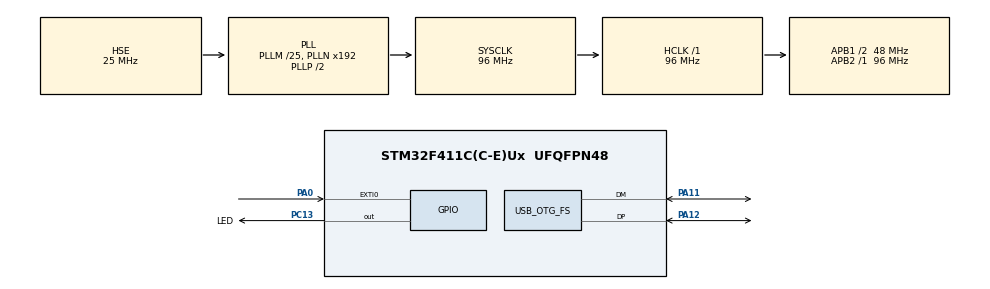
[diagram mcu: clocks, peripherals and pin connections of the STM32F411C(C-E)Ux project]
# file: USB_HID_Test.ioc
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FREERTOS.INCLUDE_pcTaskGetTaskName=1
FREERTOS.Tasks01=ledTask,24,2000,StartDefaultTask,Default,NULL,Static,ledTaskBuffer,ledTaskControlBlock
FREERTOS.configCHECK_FOR_STACK_OVERFLOW=1
FREERTOS.configMINIMAL_STACK_SIZE=1000
FREERTOS.configRECORD_STACK_HIGH_ADDRESS=1
FREERTOS.configUSE_APPLICATION_TASK_TAG=1
FREERTOS.configUSE_NEWLIB_REENTRANT=1
Mcu.Family=STM32F4
Mcu.Name=STM32F411C(C-E)Ux
Mcu.Package=UFQFPN48
NVIC.EXTI0_IRQn=true\:5\:0\:false\:false\:true\:true\:true\:true\:true
NVIC.OTG_FS_IRQn=true\:5\:0\:false\:false\:true\:true\:true\:true\:true
NVIC.PriorityGroup=NVIC_PRIORITYGROUP_4
NVIC.TIM1_UP_TIM10_IRQn=true\:15\:0\:false\:false\:true\:false\:false\:true\:true
NVIC.TimeBase=TIM1_UP_TIM10_IRQn
NVIC.TimeBaseIP=TIM10
PA0-WKUP.Signal=GPXTI0
PA11.Mode=Device_Only
PA11.Signal=USB_OTG_FS_DM
PA12.Mode=Device_Only
PA12.Signal=USB_OTG_FS_DP
PC13-ANTI_TAMP.GPIO_Label=LED
PC13-ANTI_TAMP.PinState=GPIO_PIN_SET
PC13-ANTI_TAMP.Signal=GPIO_Output
PC14-OSC32_IN.Mode=LSE-External-Oscillator
PC14-OSC32_IN.Signal=RCC_OSC32_IN
PC15-OSC32_OUT.Mode=LSE-External-Oscillator
PC15-OSC32_OUT.Signal=RCC_OSC32_OUT
PH0\ -\ OSC_IN.Mode=HSE-External-Oscillator
PH0\ -\ OSC_IN.Signal=RCC_OSC_IN
PH1\ -\ OSC_OUT.Mode=HSE-External-Oscillator
PH1\ -\ OSC_OUT.Signal=RCC_OSC_OUT
ProjectManager.HeapSize=0x1000
ProjectManager.StackSize=0x800
ProjectManager.TargetToolchain=STM32CubeIDE
RCC.48MHZClocksFreq_Value=48000000
RCC.AHBFreq_Value=96000000
RCC.APB1CLKDivider=RCC_HCLK_DIV2
RCC.APB1Freq_Value=48000000
RCC.APB1TimFreq_Value=96000000
RCC.APB2Freq_Value=96000000
RCC.APB2TimFreq_Value=96000000
RCC.CortexFreq_Value=96000000
RCC.HCLKFreq_Value=96000000
RCC.HSE_VALUE=25000000
RCC.HSI_VALUE=16000000
RCC.PLLM=25
RCC.SYSCLKFreq_VALUE=96000000
RCC.SYSCLKSource=RCC_SYSCLKSOURCE_PLLCLK
RCC.VCOOutputFreq_Value=192000000
USB_OTG_FS.VirtualMode=Device_Only
USB_OTG_FS.low_power_enable=DISABLE
USB_OTG_FS.lpm_enable=DISABLE
VP_FREERTOS_VS_CMSIS_V2.Mode=CMSIS_V2
VP_SYS_VS_tim10.Mode=TIM10
board=custom

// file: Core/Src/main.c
/* USER CODE BEGIN Header */
/**
  ******************************************************************************
  * @file           : main.c
  * @brief          : Main program body
  ******************************************************************************
  * @attention
  *
  * Copyright (c) 2025 STMicroelectronics.
  * All rights reserved.
  *
  * This software is licensed under terms that can be found in the LICENSE file
  * in the root directory of this software component.
  * If no LICENSE file comes with this software, it is provided AS-IS.
  *
  ******************************************************************************
  */
/* USER CODE END Header */
#include "main.h"
#include "cmsis_os.h"
#include "gpio.h"

/* USER CODE BEGIN Includes */
#include "usb_device.h"
/* USER CODE END Includes */

void SystemClock_Config(void);
void MX_FREERTOS_Init(void);

int main(void)
{

  /* MCU Configuration--------------------------------------------------------*/

  /* Reset of all peripherals, Initializes the Flash interface and the Systick. */
  HAL_Init();

  /* Configure the system clock */
  SystemClock_Config();

  /* Initialize all configured peripherals */
  MX_GPIO_Init();
  /* USER CODE BEGIN 2 */

  MX_USB_DEVICE_Init();

  /* USER CODE END 2 */

  /* Init scheduler */
  osKernelInitialize();  /* Call init function for freertos objects (in cmsis_os2.c) */
  MX_FREERTOS_Init();

  /* Start scheduler */
  osKernelStart();

  /* We should never get here as control is now taken by the scheduler */

  /* Infinite loop */
  while (1)
  {

    /* USER CODE BEGIN 3 */
	// We should never get here
  }
  /* USER CODE END 3 */
}

void SystemClock_Config(void)
{
  RCC_OscInitTypeDef RCC_OscInitStruct = {0};
  RCC_ClkInitTypeDef RCC_ClkInitStruct = {0};

  /** Configure the main internal regulator output voltage
  */
  __HAL_RCC_PWR_CLK_ENABLE();
  __HAL_PWR_VOLTAGESCALING_CONFIG(PWR_REGULATOR_VOLTAGE_SCALE1);

  /** Initializes the RCC Oscillators according to the specified parameters
  * in the RCC_OscInitTypeDef structure.
  */
  RCC_OscInitStruct.OscillatorType = RCC_OSCILLATORTYPE_HSE;
  RCC_OscInitStruct.HSEState = RCC_HSE_ON;
  RCC_OscInitStruct.PLL.PLLState = RCC_PLL_ON;
  RCC_OscInitStruct.PLL.PLLSource = RCC_PLLSOURCE_HSE;
  RCC_OscInitStruct.PLL.PLLM = 25;
  RCC_OscInitStruct.PLL.PLLN = 192;
  RCC_OscInitStruct.PLL.PLLP = RCC_PLLP_DIV2;
  RCC_OscInitStruct.PLL.PLLQ = 4;
  if (HAL_RCC_OscConfig(&RCC_OscInitStruct) != HAL_OK)
  {
    Error_Handler();
  }

  /** Initializes the CPU, AHB and APB buses clocks
  */
  RCC_ClkInitStruct.ClockType = RCC_CLOCKTYPE_HCLK|RCC_CLOCKTYPE_SYSCLK
                              |RCC_CLOCKTYPE_PCLK1|RCC_CLOCKTYPE_PCLK2;
  RCC_ClkInitStruct.SYSCLKSource = RCC_SYSCLKSOURCE_PLLCLK;
  RCC_ClkInitStruct.AHBCLKDivider = RCC_SYSCLK_DIV1;
  RCC_ClkInitStruct.APB1CLKDivider = RCC_HCLK_DIV2;
  RCC_ClkInitStruct.APB2CLKDivider = RCC_HCLK_DIV1;

  if (HAL_RCC_ClockConfig(&RCC_ClkInitStruct, FLASH_LATENCY_3) != HAL_OK)
  {
    Error_Handler();
  }
}

void HAL_TIM_PeriodElapsedCallback(TIM_HandleTypeDef *htim)
{
  if (htim->Instance == TIM10)
  {
    HAL_IncTick();
  }
}

void Error_Handler(void)
{
  __disable_irq();
  while (1)
  {
  }
}

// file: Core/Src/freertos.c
/* USER CODE BEGIN Header */
/**
  ******************************************************************************
  * File Name          : freertos.c
  * Description        : Code for freertos applications
  ******************************************************************************
  * @attention
  *
  * Copyright (c) 2025 STMicroelectronics.
  * All rights reserved.
  *
  * This software is licensed under terms that can be found in the LICENSE file
  * in the root directory of this software component.
  * If no LICENSE file comes with this software, it is provided AS-IS.
  *
  ******************************************************************************
  */
/* USER CODE END Header */

#include "FreeRTOS.h"
#include "task.h"
#include "main.h"
#include "cmsis_os.h"

/* USER CODE BEGIN Includes */
#include "usbd_custom_hid_if.h"
/* USER CODE END Includes */

typedef StaticTask_t osStaticThreadDef_t;

/* Definitions for ledTask */
osThreadId_t ledTaskHandle;
uint32_t ledTaskBuffer[ 2000 ];
osStaticThreadDef_t ledTaskControlBlock;
const osThreadAttr_t ledTask_attributes = {
  .name = "ledTask",
  .cb_mem = &ledTaskControlBlock,
  .cb_size = sizeof(ledTaskControlBlock),
  .stack_mem = &ledTaskBuffer[0],
  .stack_size = sizeof(ledTaskBuffer),
  .priority = (osPriority_t) osPriorityNormal,
};

void StartDefaultTask(void *argument);

void MX_FREERTOS_Init(void); /* (MISRA C 2004 rule 8.1) */

/* Hook prototypes */
void vApplicationStackOverflowHook(xTaskHandle xTask, signed char *pcTaskName);

/* USER CODE BEGIN 4 */
void vApplicationStackOverflowHook(xTaskHandle xTask, signed char *pcTaskName)
{
   /* Run time stack overflow checking is performed if
   configCHECK_FOR_STACK_OVERFLOW is defined to 1 or 2. This hook function is
   called if a stack overflow is detected. */
}
/* USER CODE END 4 */

void MX_FREERTOS_Init(void) {

  /* Create the thread(s) */
  /* creation of ledTask */
  ledTaskHandle = osThreadNew(StartDefaultTask, NULL, &ledTask_attributes);

}

void StartDefaultTask(void *argument)
{
  /* USER CODE BEGIN StartDefaultTask */
	static uint8_t input_report_data[64];
	input_report_data[0] = 1; // Input report ID
	for (int i = 0; i < 63; i++) {
		input_report_data[i + 1] = i;
	}

  /* Infinite loop */
	for(;;)
	{
		HAL_GPIO_TogglePin(LED_GPIO_Port, LED_Pin);
		osDelay(300);

		USBD_CUSTOM_HID_SendReport_FS(input_report_data, sizeof(input_report_data));
	}
  /* USER CODE END StartDefaultTask */
}
